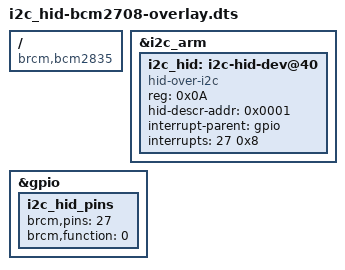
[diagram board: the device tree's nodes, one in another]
// Definitions for HID over I2C
/dts-v1/;
/plugin/;

/{
	compatible = "brcm,bcm2835", "brcm,bcm2708", "brcm,bcm2709";

	fragment@0 {
		target = <&i2c_arm>;
		__overlay__ {
			status = "okay";
		};
	};
	
	fragment@1 {
		target = <&gpio>;
		__overlay__ {
			i2c_hid_pins: i2c_hid_pins {
				brcm,pins = <27>;
				brcm,function = <0>;
			};
		};
	};
	
	fragment@2 {
		target = <&i2c_arm>;
		__overlay__{
			#address-cells = <1>;
			#size-cells = <0>;

			i2c_hid: i2c-hid-dev@40 {
				compatible = "hid-over-i2c";
				reg = <0x0A>;
				hid-descr-addr = <0x0001>;
				interrupt-parent = <&gpio>;
				interrupts = <27 0x8>;
			};
			
		};
	};
	
	__overrides__ {
		gpiopin = <&i2c_hid_pins>, "brcm,pins:0",
					<&i2c_hid>, "interrupts:0";
		addr = <&i2c_hid>, "reg:0";
		};
		
};
